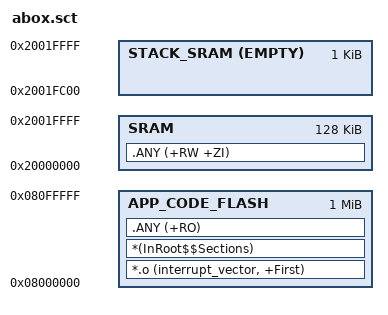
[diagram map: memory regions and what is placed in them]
; *************************************************************
; *** Scatter-Loading Description File generated by hexin   ***
; *** Copyright 2018, hexin (dalian)                        ***
; *************************************************************

LR_IROM1            0x08000000    0x00100000    { ; load region size_region
    APP_CODE_FLASH  0x08000000    0x00100000    { ; load address = execution address
    *.o (interrupt_vector, +First)                ; platform_vector_table.c
    *(InRoot$$Sections)
    .ANY (+RO)
    }
    SRAM            0x20000000    0x00020000    { ; RW data (sum=128KB)
    .ANY (+RW +ZI)
    }
    STACK_SRAM      0x20020000    EMPTY -0x400  { ; Stack at the end.
    }
}
